# psoc6_03 register map
Vendor: Cypress Semiconductor; Series: PSoC6_03; File version: 1.0
CPU: CM4 r0p1, little endian, MPU, FPU, VTOR, 3 interrupt priority bits
Registers are 32-bit, read-write, reset 0x0 unless marked. A register's access mark holds for its fields unless they carry their own. Offsets are from the block's base; [hi:lo] are bit positions; lines under a group give offsets from that group; {n}, {i} and the like mark numbered series.

## DMAC
Base 0x402A0000
0x00 CTL — Control
  [31] ENABLED — IP enable: '0': Disabled. All non-retention registers (command and status registers) are reset to their default value when the IP is disabled. All retention registers retain their value when the IP is disabled. '1': Enabled.
    0=DISABLED (N/A); 1=ENABLED (N/A)
0x08 ACTIVE ro — Active channels
  [7:0] ACTIVE — Specifies active channels; i.e. enabled channels whose trigger got activated.
{0x1000+0x100*i} CH[{i}] (i=0..1) group — DMA controller channel
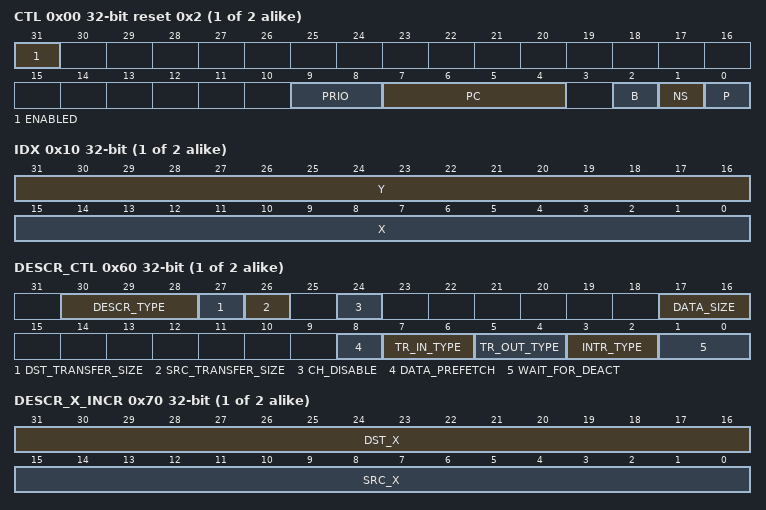
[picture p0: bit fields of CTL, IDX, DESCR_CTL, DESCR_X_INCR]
  0x00 CTL reset 0x2 — Channel control
    [31] ENABLED — Channel enable: '0': Disabled. The channel's trigger is ignored and the channel cannot be made pending and therefore cannot be made active. If a pending channel is disabled, the channel is made non pending. If the activate channel is disabled, the channel is de-activated (bus transactions are completed). '1': Enabled. SW sets this field to '1' to enable a specific channel. HW sets this field to '0' when an error interrupt cause is activated.
    [9:8] PRIO — Channel priority: '0': highest priority. '1' '2' '3': lowest priority. Channels with the same priority constitute a priority group and within this priority group, the following 'roundrobin' arbitration is applied. A 'round' consists of a contiguous sequence of channel activations, within this priority group, without any repetition. Within a round, higher priority is given to the lower channel indices. The notion of a round guarantees that within a group, higher channel indices do not yield to lower indices indefinitely.
    [7:4] PC — Protection context. This field is set with the protection context of the transaction that writes this register; i.e. the context is inherited from the write transaction and not specified by the transaction write data. All transactions for this channel uses the PC field for the protection context.
    [2] B — Non-bufferable/bufferable access control: '0': non-bufferable. '1': bufferable. This field is used to indicate to an AMBA bridge that a write transaction can complete without waiting for the destination to accept the write transaction data. All transactions for this channel uses the B field for the non-bufferable/bufferable access control ('hprot[2]').
    [1] NS — Secure/on-secure access control: '0': secure. '1': non-secure. This field is set with the secure/non-secure access control of the transaction that writes this register; i.e. the access control is inherited from the write transaction and not specified by the transaction write data. All transactions for this channel use the NS field for the secure/non-secure access control ('hprot[4]').
    [0] P — User/privileged access control: '0': user mode. '1': privileged mode. This field is set with the user/privileged access control of the transaction that writes this register; i.e. the access control is inherited from the write transaction and not specified by the transaction write data. All transactions for this channel use the P field for the user/privileged access control ('hprot[1]').
  0x10 IDX ro reset not defined — Channel current indices
    [31:16] Y — Specifies the Y loop index, with Y_COUNT taken from the current descriptor. Note: HW sets this field to '0' when it loads a descriptor..
    [15:0] X — Specifies the X loop index. In the range of [0, X_COUNT], with X_COUNT taken from the current descriptor. Note: HW sets this field to '0' when it loads a descriptor.
  0x14 SRC ro reset not defined — Channel current source address
    [31:0] ADDR — Current address of source location.
  0x18 DST ro reset not defined — Channel current destination address
    [31:0] ADDR — Current address of destination location.
  0x20 CURR reset not defined — Channel current descriptor pointer
    [31:2] PTR — Address of current descriptor. When this field is '0', there is no valid descriptor. Note: HW updates the current descriptor pointer CH_CURR_PTR with DESCR_NEXT_PTR after execution of the current descriptor.
  0x28 TR_CMD — Channle software trigger
    [0] ACTIVATE — Software trigger. When written with '1', a trigger is generated which sets 'trigger pending' (only if the channel is enabled). A read always returns a 0.
  0x40 DESCR_STATUS ro — Channel descriptor status
    [31] VALID — Indicates whether the descriptor information present in DESCR_CTL, DESCR_SRC, DESCR_DST, DESCR_X_SIZE, DESCR_X_INCR, DESCR_Y_SIZE, DESCR_Y_INCR, DESCR_NEXT status registers is valid or not.
  0x60 DESCR_CTL ro reset not defined — Channel descriptor control
    [30:28] DESCR_TYPE, [27] DST_TRANSFER_SIZE, [26] SRC_TRANSFER_SIZE, [24] CH_DISABLE, [17:16] DATA_SIZE, [8] DATA_PREFETCH, [7:6] TR_IN_TYPE, [5:4] TR_OUT_TYPE, [3:2] INTR_TYPE, [1:0] WAIT_FOR_DEACT
  0x64 DESCR_SRC ro reset not defined — Channel descriptor source
    [31:0] ADDR
  0x68 DESCR_DST ro reset not defined — Channel descriptor destination
    [31:0] ADDR
  0x6C DESCR_X_SIZE ro reset not defined — Channel descriptor X size
    [15:0] X_COUNT
  0x70 DESCR_X_INCR ro reset not defined — Channel descriptor X increment
    [31:16] DST_X, [15:0] SRC_X
  0x74 DESCR_Y_SIZE ro reset not defined — Channel descriptor Y size
    [15:0] Y_COUNT
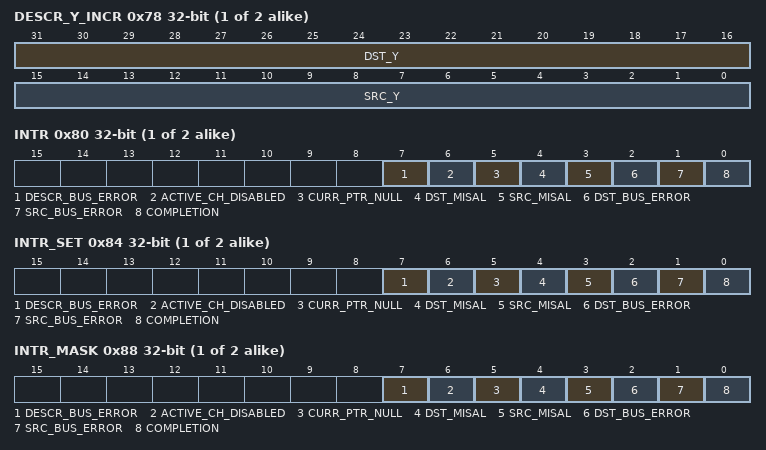
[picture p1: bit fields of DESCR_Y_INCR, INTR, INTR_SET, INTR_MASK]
  0x78 DESCR_Y_INCR ro reset not defined — Channel descriptor Y increment
    [31:16] DST_Y, [15:0] SRC_Y
  0x7C DESCR_NEXT ro reset not defined — Channel descriptor next pointer
    [31:2] PTR
  0x80 INTR — Interrupt
    [7] DESCR_BUS_ERROR — Activated (set to '1') on a bus error for a load of the descriptor.
    [6] ACTIVE_CH_DISABLED — Activated (set to '1') if the channel is disabled by SW (accidentally/incorrectly) when the data transfer engine is busy.
    [5] CURR_PTR_NULL — Activated (set to '1') when the channel is enabled (CH_CTL.ENABLED is '1') and CH_CURR_PTR is '0'.
    [4] DST_MISAL — Activated (set to '1') on a misalignment of the destination address.
    [3] SRC_MISAL — Activated (set to '1') on a misalignment of the source address.
    [2] DST_BUS_ERROR — Activated (set to '1') on a bus error for a store to the destination.
    [1] SRC_BUS_ERROR — Activated (set to '1') on a bus error for a load from the source.
    [0] COMPLETION — Activated (set to '1') on completion of data transfer(s) as specified by the descriptor's CH_DESCR_CTL.INTR_TYPE.
  0x84 INTR_SET — Interrupt set
    [7] DESCR_BUS_ERROR
    [6] ACTIVE_CH_DISABLED
    [5] CURR_PTR_NULL
    [4] DST_MISAL
    [3] SRC_MISAL
    [2] DST_BUS_ERROR
    [1] SRC_BUS_ERROR
    [0] COMPLETION — Write this field with '1' to set corresponding INTR field to '1' (a write of '0' has no effect).
  0x88 INTR_MASK — Interrupt mask
    [7] DESCR_BUS_ERROR
    [6] ACTIVE_CH_DISABLED
    [5] CURR_PTR_NULL
    [4] DST_MISAL
    [3] SRC_MISAL
    [2] DST_BUS_ERROR
    [1] SRC_BUS_ERROR
    [0] COMPLETION — Mask for corresponding field in INTR register.
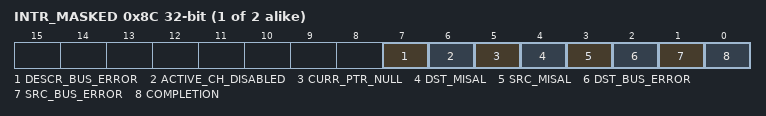
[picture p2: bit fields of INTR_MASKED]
  0x8C INTR_MASKED ro — Interrupt masked
    [7] DESCR_BUS_ERROR
    [6] ACTIVE_CH_DISABLED
    [5] CURR_PTR_NULL
    [4] DST_MISAL
    [3] SRC_MISAL
    [2] DST_BUS_ERROR
    [1] SRC_BUS_ERROR
    [0] COMPLETION — Logical and of corresponding INTR and INTR_MASK fields.
